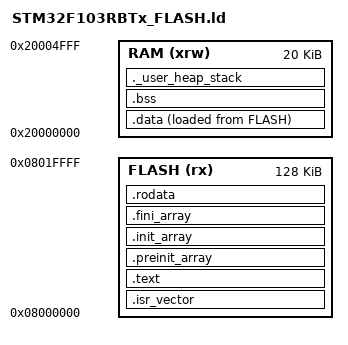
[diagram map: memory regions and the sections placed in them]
/*
******************************************************************************
**  STM32F103RB Linker Script (STM32F103RBT6 - 128KB Flash, 20KB RAM)
**
**  Memory layout:
**    FLASH:  0x08000000 - 0x0801FFFF  (128 KB)
**    SRAM:   0x20000000 - 0x20004FFF  (20 KB)
**
******************************************************************************
*/

MEMORY
{
    FLASH (rx)  : ORIGIN = 0x08000000, LENGTH = 128K
    RAM   (xrw) : ORIGIN = 0x20000000, LENGTH = 20K
}

/* Entry Point */
ENTRY(Reset_Handler)

/* Highest address of the user mode stack */
_estack = ORIGIN(RAM) + LENGTH(RAM);

/* Sections */
SECTIONS
{
    /* The startup code goes first into FLASH */
    .isr_vector :
    {
        . = ALIGN(4);
        KEEP(*(.isr_vector))
        . = ALIGN(4);
    } > FLASH

    /* The program code and other data goes into FLASH */
    .text :
    {
        . = ALIGN(4);
        *(.text)
        *(.text.*)
        *(.glue_7)
        *(.glue_7t)
        *(.gcc_except_table)
        *(.gnu.linkonce.t.*)

        . = ALIGN(4);
        KEEP(*(.init))
        KEEP(*(.fini))
    } > FLASH

    /* ARM Cortex-M3 constructor/destructor */
    .preinit_array :
    {
        PROVIDE_HIDDEN(__preinit_array_start = .);
        KEEP(*(.preinit_array*))
        PROVIDE_HIDDEN(__preinit_array_end = .);
    } > FLASH

    .init_array :
    {
        PROVIDE_HIDDEN(__init_array_start = .);
        KEEP(*(SORT(.init_array.*)))
        KEEP(*(.init_array*))
        PROVIDE_HIDDEN(__init_array_end = .);
    } > FLASH

    .fini_array :
    {
        PROVIDE_HIDDEN(__fini_array_start = .);
        KEEP(*(SORT(.fini_array.*)))
        KEEP(*(.fini_array*))
        PROVIDE_HIDDEN(__fini_array_end = .);
    } > FLASH

    /* Constant data */
    .rodata :
    {
        . = ALIGN(4);
        *(.rodata)
        *(.rodata.*)
        *(.gnu.linkonce.r.*)
        . = ALIGN(4);
    } > FLASH

    /* Pointers to static and global data */
    _sidata = LOADADDR(.data);

    /* Initialized data section */
    .data :
    {
        . = ALIGN(4);
        _sdata = .;
        *(.data)
        *(.data.*)
        *(.gnu.linkonce.d.*)
        . = ALIGN(4);
        _edata = .;
    } > RAM AT > FLASH

    /* Uninitialized data section */
    .bss :
    {
        . = ALIGN(4);
        _sbss = .;
        __bss_start__ = _sbss;
        *(.bss)
        *(.bss.*)
        *(.gnu.linkonce.b.*)
        *(COMMON)
        . = ALIGN(4);
        _ebss = .;
        __bss_end__ = _ebss;
    } > RAM

    /* User_heap_stack area */
    ._user_heap_stack :
    {
        . = ALIGN(8);
        PROVIDE(end = .);
        PROVIDE(_end = .);
        . = . + 0x800;  /* 2KB heap */
        . = ALIGN(8);
        . = . + 0x800;  /* 2KB stack */
        . = ALIGN(8);
    } > RAM

    /* Discard unnecessary sections */
    /DISCARD/ :
    {
        libc.a(*)()
        libm.a(*)()
        libgcc.a(*)()
    }

    .ARM.attributes 0 : { *(.ARM.attributes) }
}
